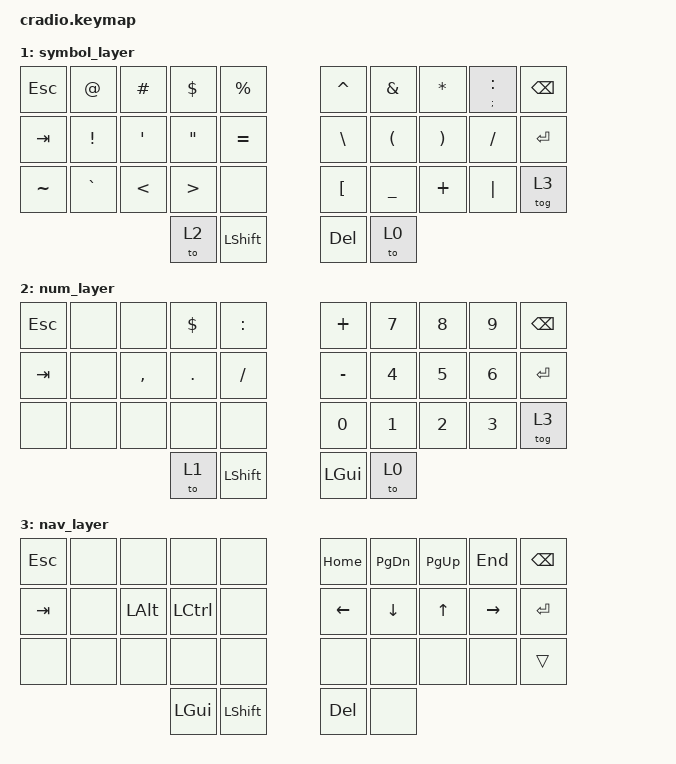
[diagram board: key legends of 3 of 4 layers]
// Copyright (c) 2022 The ZMK Contributors
// SPDX-License-Identifier: MIT

#include <behaviors.dtsi>
#include <dt-bindings/zmk/keys.h>
#include <dt-bindings/zmk/bt.h>

// Home row mods macro
#define HRML(k1,k2) &ht LALT k1  &ht LCTL k2
#define HRMR(k1,k2) &ht LCTL k1  &ht LALT k2  

#define DEFAULT 0
#define SYMBOLS 1
#define NUMBERS 2
#define NAV 3

/ {
    behaviors {
        ht: hold_tap {
            label = "hold_tap";
            compatible = "zmk,behavior-hold-tap";
            #binding-cells = <2>;
            flavor = "tap-preferred";
            tapping-term-ms = <170>;
            quick-tap-ms = <100>;
            global-quick-tap;
            bindings = <&kp>, <&kp>;
        };
    };


    keymap {
        compatible = "zmk,keymap";
        default_layer {
            bindings = <
        //╭──────────┬──────────┬──────────┬──────────┬──────────╮   ╭──────────┬──────────┬──────────┬──────────┬──────────╮
        //│  Q       │  W       │  F       │  P       │  B       │   │  J       │  L       │  U       │  Y       │  -  _    │
            &kp Q      &kp W      &kp F      &kp P      &kp B          &kp J      &kp L      &kp U      &kp Y      &ht MINUS UNDER
        //├──────────┼──────────┼──────────┼──────────┼──────────┤   ├──────────┼──────────┼──────────┼──────────┼──────────┤
        //│  A       │  R       │  S       │  T       │  G       │   │  M       │  N       │  E       │  L       │  O       │
            &kp A     &kp  R     HRML(S,         T)     &kp G          &kp M     HRMR(N,         E)     &kp I      &kp O
        //├──────────┼──────────┼──────────┼──────────┼──────────┤   ├──────────┼──────────┼──────────┼──────────┼──────────┤
        //│  Z       │  X       │  C       │  D       │  V       │   │  K       │  H       │ , <      │ . >      │ / ?      │
            &kp Z      &kp X      &kp C      &kp D      &kp V          &kp K      &kp H   &ht COMMA LT &ht DOT GT  &ht FSLH QMARK
        //╰──────────┴──────────┴──────────┼──────────┼──────────┤   ├──────────┼──────────┼──────────┴──────────┴──────────╯
                                            &to 1    &mt LSHFT CAPS    &kp LGUI   &kp SPACE
        //                                 ╰──────────┴──────────╯   ╰──────────┴──────────╯
            >;
        };

        symbol_layer {
            bindings = <
        //╭──────────┬──────────┬──────────┬──────────┬──────────╮   ╭──────────┬──────────┬──────────┬──────────┬──────────╮
        //│  ESC     │  @       │  #       │  $       │    %     │   │  ^       │  &       │  *       │  ; :     │  BSPC    │
            &kp ESC     &kp AT   &kp HASH   &kp DLLR   &kp PRCNT       &kp CARET   &kp AMPS   &kp ASTRK &ht SEMI COLON &kp BSPC
        //├──────────┼──────────┼──────────┼──────────┼──────────┤   ├──────────┼──────────┼──────────┼──────────┼──────────┤
        //│  TAB     │  !       │  '       │  "       │  =       │   │  \       │  (       │  )       │  /       │  ENTER   │
            &kp TAB   &kp EXCL    &kp SQT   &kp DQT    &kp EQUAL       &kp BSLH    &kp LPAR   &kp RPAR  &kp FSLH    &kp ENTER
        //├──────────┼──────────┼──────────┼──────────┼──────────┤   ├──────────┼──────────┼──────────┼──────────┼──────────┤
        //│   ~      │   `      │  <       │  >       │  N/A     │   │  [       │  {       │  }       │  ]       │  TG NAV  │
            &kp TILDE  &kp GRAVE   &kp LT     &kp GT   &none          &kp LBKT    &kp UNDER  &kp PLUS   &kp PIPE   &tog 3
        //╰──────────┴──────────┴──────────┼──────────┼──────────┤   ├──────────┼──────────┼──────────┴──────────┴──────────╯
                                             &to 2     &kp LSHFT       &kp DEL    &to 0
        //                                 ╰──────────┴──────────╯   ╰──────────┴──────────╯
            >;
        };

        num_layer {
            bindings = <
        //╭──────────┬──────────┬──────────┬──────────┬──────────╮    ╭──────────┬──────────┬──────────┬──────────┬─────────╮
        //│ ESC      │          │          │   $      │  *       │    │   +      │  7       │  8       │   9      │  BSPC   │
            &kp ESC    &none      &none     &kp DLLR   &kp COLON       &kp PLUS   &kp N7     &kp N8     &kp N9     &kp BSPC
        //├──────────┼──────────┼──────────┼──────────┼──────────┤    ├──────────┼──────────┼──────────┼──────────┤─────────┤
        //│ TAB      │          │  ,       │   .      │  /       │    │  -       │  4       │  5       │   6      │ ENTER   │
            &kp TAB    &none     &kp COMMA  &kp DOT    &kp FSLH        &kp MINUS  &kp N4     &kp N5     &kp N6     &kp ENTER
        //├──────────┼──────────┼──────────┼──────────┼──────────┤    ├──────────┼──────────┼──────────┼──────────┤─────────┤
        //│ TG GAME  │          │          │          │          │    │  0       │  1       │  2       │   3      │  TG NAV │
           &none       &none     &none      &none      &none           &kp N0     &kp N1     &kp N2     &kp N3     &tog 3
        //╰──────────┼──────────┼──────────┴──────────┴──────────╯    ├──────────┴──────────┼──────────┼──────────┤─────────╯
                                             &to 1     &kp LSHFT       &kp LGUI     &to 0
        //                                 ╰──────────┴──────────╯   ╰──────────┴──────────╯
            >;
        };

        nav_layer {
            bindings = <
        //╭──────────┬──────────┬──────────┬──────────┬──────────╮    ╭──────────┬──────────┬──────────┬──────────┬─────────╮
        //│ ESC      │          │          │          │          │    │   HOME   │          │          │   END    │  BSPC   │
            &kp ESC    &none      &none     &none      &none           &kp HOME   &kp PG_DN   &kp PG_UP  &kp END    &kp BSPC
        //├──────────┼──────────┼──────────┼──────────┼──────────┤    ├──────────┼──────────┼──────────┼──────────┤─────────┤
        //│ TAB      │          │          │          │          │    │  <-       │         │     ^    │   ->      │ ENTER   │
            &kp TAB    &none      &kp LALT  &kp LCTRL  &none         &kp LEFT   &kp DOWN    &kp UP     &kp RIGHT  &kp ENTER
        //├──────────┼──────────┼──────────┼──────────┼──────────┤    ├──────────┼──────────┼──────────┼──────────┤─────────┤
        //│ TG GAME  │          │          │          │          │    │          │          │          │          │  TG NAV │
           &none       &none      &none     &none      &none           &none      &none       &none      &none      &trans
        //╰──────────┼──────────┼──────────┴──────────┴──────────╯    ├──────────┴──────────┼──────────┼──────────┤─────────╯
                                             &kp LGUI  &kp LSHFT       &kp DEL    &none
        //                                 ╰──────────┴──────────╯   ╰──────────┴──────────╯
            >;
        };

    };
};
